AUTOSAR XML (schema 4-2-2)
package /STELLANTIS/EPT/ASWCs
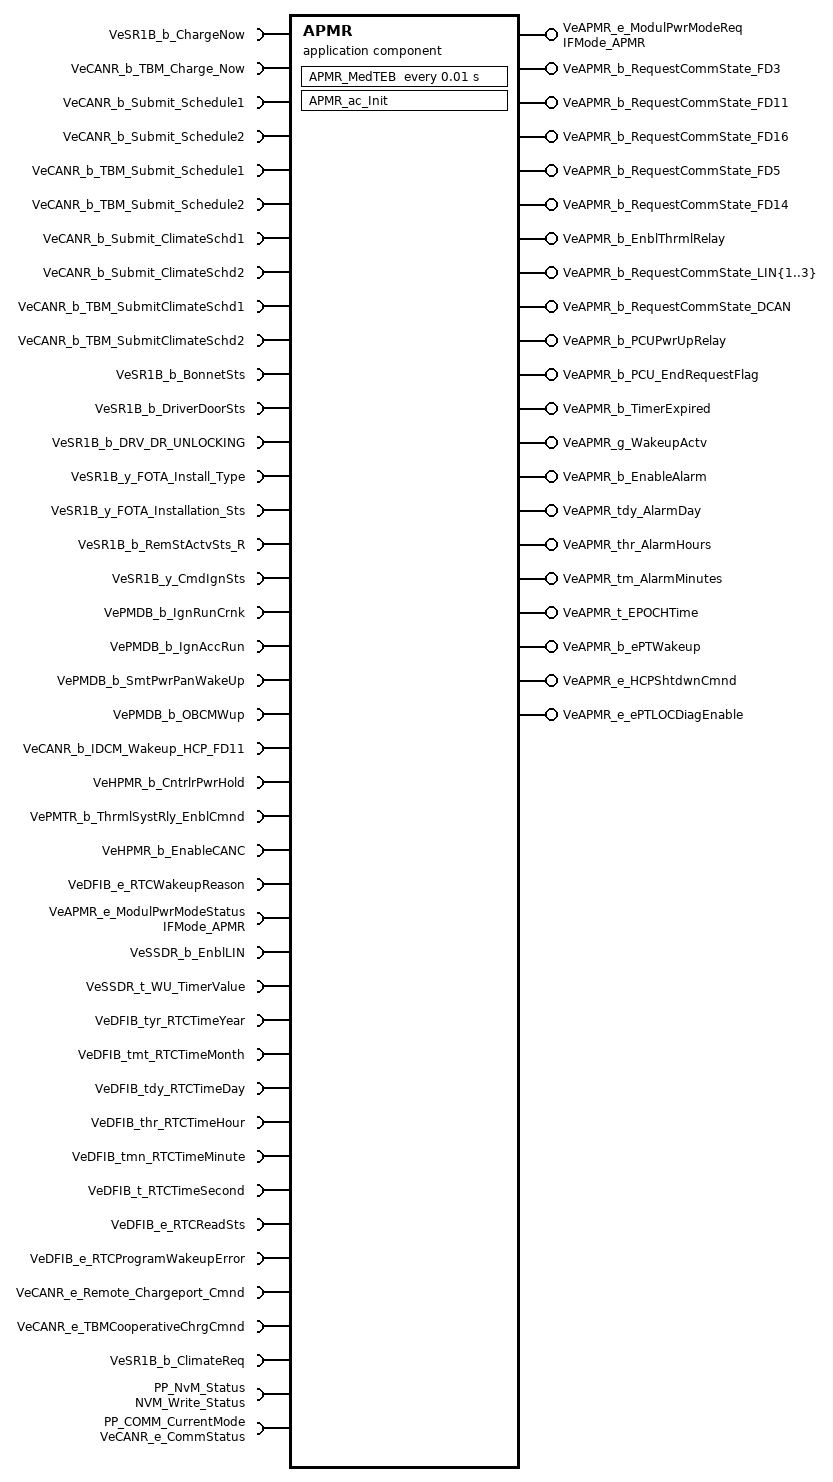
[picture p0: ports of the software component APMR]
  application sw component type APMR
    42 x require port:
      VeSR1B_b_ChargeNow: nonqueued-receiver-com-spec{data-element=Value, init-value=0}, required-interface=VeSR1B_b_ChargeNow
      VeCANR_b_TBM_Charge_Now: nonqueued-receiver-com-spec{data-element=VeCANR_b_TBM_Charge_Now, init-value=0}, required-interface=VeCANR_b_TBM_Charge_Now
      VeCANR_b_Submit_Schedule1: nonqueued-receiver-com-spec{data-element=VeCANR_b_Submit_Schedule1, init-value=0}, required-interface=VeCANR_b_Submit_Schedule1
      VeCANR_b_Submit_Schedule2: nonqueued-receiver-com-spec{data-element=VeCANR_b_Submit_Schedule2, init-value=0}, required-interface=VeCANR_b_Submit_Schedule2
      VeCANR_b_TBM_Submit_Schedule1: nonqueued-receiver-com-spec{data-element=VeCANR_b_TBM_Submit_Schedule1, init-value=0}, required-interface=VeCANR_b_TBM_Submit_Schedule1
      VeCANR_b_TBM_Submit_Schedule2: nonqueued-receiver-com-spec{data-element=VeCANR_b_TBM_Submit_Schedule2, init-value=0}, required-interface=VeCANR_b_TBM_Submit_Schedule2
      VeCANR_b_Submit_ClimateSchd1: nonqueued-receiver-com-spec{data-element=VeCANR_b_Submit_ClimateSchd1, init-value=0}, required-interface=VeCANR_b_Submit_ClimateSchd1
      VeCANR_b_Submit_ClimateSchd2: nonqueued-receiver-com-spec{data-element=VeCANR_b_Submit_ClimateSchd2, init-value=0}, required-interface=VeCANR_b_Submit_ClimateSchd2
      VeCANR_b_TBM_SubmitClimateSchd1: nonqueued-receiver-com-spec{data-element=VeCANR_b_TBM_SubmitClimateSchd1, init-value=0}, required-interface=VeCANR_b_TBM_SubmitClimateSchd1
      VeCANR_b_TBM_SubmitClimateSchd2: nonqueued-receiver-com-spec{data-element=VeCANR_b_TBM_SubmitClimateSchd2, init-value=0}, required-interface=VeCANR_b_TBM_SubmitClimateSchd2
      VeSR1B_b_BonnetSts: nonqueued-receiver-com-spec{data-element=Value, init-value=0}, required-interface=VeSR1B_b_BonnetSts
      VeSR1B_b_DriverDoorSts: nonqueued-receiver-com-spec{data-element=Value, init-value=0}, required-interface=VeSR1B_b_DriverDoorSts
      VeSR1B_b_DRV_DR_UNLOCKING: nonqueued-receiver-com-spec{data-element=Value, init-value=0}, required-interface=VeSR1B_b_DRV_DR_UNLOCKING
      VeSR1B_y_FOTA_Install_Type: nonqueued-receiver-com-spec{data-element=Value, init-value=0}, required-interface=VeSR1B_y_FOTA_Install_Type
      VeSR1B_y_FOTA_Installation_Sts: nonqueued-receiver-com-spec{data-element=Value, init-value=0}, required-interface=VeSR1B_y_FOTA_Installation_Sts
      VeSR1B_b_RemStActvSts_R: nonqueued-receiver-com-spec{data-element=Value, init-value=0}, required-interface=VeSR1B_b_RemStActvSts_R
      VeSR1B_y_CmdIgnSts: nonqueued-receiver-com-spec{data-element=Value, init-value=0}, required-interface=VeSR1B_y_CmdIgnSts
      VePMDB_b_IgnRunCrnk: nonqueued-receiver-com-spec{data-element=Value, init-value=0}, required-interface=VePMDB_b_IgnRunCrnk
      VePMDB_b_IgnAccRun: nonqueued-receiver-com-spec{data-element=Value, init-value=0}, required-interface=VePMDB_b_IgnAccRun
      VePMDB_b_SmtPwrPanWakeUp: nonqueued-receiver-com-spec{data-element=Value, init-value=0}, required-interface=VePMDB_b_SmtPwrPanWakeUp
      VePMDB_b_OBCMWup: nonqueued-receiver-com-spec{data-element=Value, init-value=0}, required-interface=VePMDB_b_OBCMWup
      VeCANR_b_IDCM_Wakeup_HCP_FD11: nonqueued-receiver-com-spec{data-element=VeCANR_b_IDCM_Wakeup_HCP_FD11, init-value=0}, required-interface=VeCANR_b_IDCM_Wakeup_HCP_FD11
      VeHPMR_b_CntrlrPwrHold: nonqueued-receiver-com-spec{data-element=Value, init-value=0}, required-interface=VeHPMR_b_CntrlrPwrHold
      VePMTR_b_ThrmlSystRly_EnblCmnd: nonqueued-receiver-com-spec{data-element=Value, init-value=0}, required-interface=VePMTR_b_ThrmlSystRly_EnblCmnd
      VeHPMR_b_EnableCANC: nonqueued-receiver-com-spec{data-element=Value, init-value=0}, required-interface=VeHPMR_b_EnableCANC
      VeDFIB_e_RTCWakeupReason: nonqueued-receiver-com-spec{data-element=Value, init-value=CeDFIB_e_RTC_NO_WAKEUP}, required-interface=VeDFIB_e_RTCWakeupReason
      VeAPMR_e_ModulPwrModeStatus: nonqueued-receiver-com-spec{data-element=Mode, init-value=0}, required-interface=IFMode_APMR
      VeSSDR_b_EnblLIN: nonqueued-receiver-com-spec{data-element=Value, init-value=0}, required-interface=VeSSDR_b_EnblLIN
      VeSSDR_t_WU_TimerValue: nonqueued-receiver-com-spec{data-element=Value, init-value=0}, required-interface=VeSSDR_t_WU_TimerValue
      VeDFIB_tyr_RTCTimeYear: nonqueued-receiver-com-spec{data-element=Value, init-value=0}, required-interface=VeDFIB_tyr_RTCTimeYear
      VeDFIB_tmt_RTCTimeMonth: nonqueued-receiver-com-spec{data-element=Value, init-value=0}, required-interface=VeDFIB_tmt_RTCTimeMonth
      VeDFIB_tdy_RTCTimeDay: nonqueued-receiver-com-spec{data-element=Value, init-value=0}, required-interface=VeDFIB_tdy_RTCTimeDay
      VeDFIB_thr_RTCTimeHour: nonqueued-receiver-com-spec{data-element=Value, init-value=0}, required-interface=VeDFIB_thr_RTCTimeHour
      VeDFIB_tmn_RTCTimeMinute: nonqueued-receiver-com-spec{data-element=Value, init-value=0}, required-interface=VeDFIB_tmn_RTCTimeMinute
      VeDFIB_t_RTCTimeSecond: nonqueued-receiver-com-spec{data-element=Value, init-value=0}, required-interface=VeDFIB_t_RTCTimeSecond
      VeDFIB_e_RTCReadSts: nonqueued-receiver-com-spec{data-element=Value, init-value=CeDFIB_e_RTCCallInit}, required-interface=VeDFIB_e_RTCReadSts
      VeDFIB_e_RTCProgramWakeupError: nonqueued-receiver-com-spec{data-element=Value, init-value=CeDFIB_e_RTCCallInit}, required-interface=VeDFIB_e_RTCProgramWakeupError
      VeCANR_e_Remote_Chargeport_Cmnd: nonqueued-receiver-com-spec{data-element=VeCANR_e_Remote_Chargeport_Cmnd, init-value=0}, required-interface=VeCANR_e_Remote_Chargeport_Cmnd
      VeCANR_e_TBMCooperativeChrgCmnd: nonqueued-receiver-com-spec{data-element=VeCANR_e_TBMCooperativeChrgCmnd, init-value=0}, required-interface=VeCANR_e_TBMCooperativeChrgCmnd
      VeSR1B_b_ClimateReq: nonqueued-receiver-com-spec{data-element=Value, init-value=0}, required-interface=VeSR1B_b_ClimateReq
      PP_NvM_Status: nonqueued-receiver-com-spec{data-element=NVM_Multiblock_WriteStatus, init-value=NVM_REQ_OK}, required-interface=NVM_Write_Status
      PP_COMM_CurrentMode: required-interface=VeCANR_e_CommStatus
        required-com-specs:
          data-element=VeCANR_e_CommStatus_DCAN, init-value=0
          data-element=VeCANR_e_CommStatus_FD11, init-value=0
          data-element=VeCANR_e_CommStatus_FD14, init-value=0
          data-element=VeCANR_e_CommStatus_FD16, init-value=0
          data-element=VeCANR_e_CommStatus_FD3, init-value=0
          data-element=VeCANR_e_CommStatus_FD5, init-value=0
          data-element=VeCANR_e_CommStatus_LIN{1..3}, init-value=0
    23 x provide port:
      VeAPMR_e_ModulPwrModeReq: nonqueued-sender-com-spec{data-element=Mode, init-value=0}, provided-interface=IFMode_APMR
      VeAPMR_b_RequestCommState_FD3: nonqueued-sender-com-spec{data-element=Value, init-value=0}, provided-interface=VeAPMR_b_RequestCommState_FD3
      VeAPMR_b_RequestCommState_FD11: nonqueued-sender-com-spec{data-element=Value, init-value=0}, provided-interface=VeAPMR_b_RequestCommState_FD11
      VeAPMR_b_RequestCommState_FD16: nonqueued-sender-com-spec{data-element=Value, init-value=0}, provided-interface=VeAPMR_b_RequestCommState_FD16
      VeAPMR_b_RequestCommState_FD5: nonqueued-sender-com-spec{data-element=Value, init-value=0}, provided-interface=VeAPMR_b_RequestCommState_FD5
      VeAPMR_b_RequestCommState_FD14: nonqueued-sender-com-spec{data-element=Value, init-value=0}, provided-interface=VeAPMR_b_RequestCommState_FD14
      VeAPMR_b_EnblThrmlRelay: nonqueued-sender-com-spec{data-element=Value, init-value=0}, provided-interface=VeAPMR_b_EnblThrmlRelay
      VeAPMR_b_RequestCommState_LIN{1..3}: nonqueued-sender-com-spec{data-element=Value, init-value=0}, provided-interface=VeAPMR_b_RequestCommState_LIN{1..3}
      VeAPMR_b_RequestCommState_DCAN: nonqueued-sender-com-spec{data-element=Value, init-value=0}, provided-interface=VeAPMR_b_RequestCommState_DCAN
      VeAPMR_b_PCUPwrUpRelay: nonqueued-sender-com-spec{data-element=Value, init-value=0}, provided-interface=VeAPMR_b_PCUPwrUpRelay
      VeAPMR_b_PCU_EndRequestFlag: nonqueued-sender-com-spec{data-element=Value, init-value=0}, provided-interface=VeAPMR_b_PCU_EndRequestFlag
      VeAPMR_b_TimerExpired: nonqueued-sender-com-spec{data-element=Value, init-value=0}, provided-interface=VeAPMR_b_TimerExpired
      VeAPMR_g_WakeupActv: nonqueued-sender-com-spec{data-element=Value, init-value=0}, provided-interface=VeAPMR_g_WakeupActv
      VeAPMR_b_EnableAlarm: nonqueued-sender-com-spec{data-element=Value, init-value=0}, provided-interface=VeAPMR_b_EnableAlarm
      VeAPMR_tdy_AlarmDay: nonqueued-sender-com-spec{data-element=Value, init-value=0}, provided-interface=VeAPMR_tdy_AlarmDay
      VeAPMR_thr_AlarmHours: nonqueued-sender-com-spec{data-element=Value, init-value=0}, provided-interface=VeAPMR_thr_AlarmHours
      VeAPMR_tm_AlarmMinutes: nonqueued-sender-com-spec{data-element=Value, init-value=0}, provided-interface=VeAPMR_tm_AlarmMinutes
      VeAPMR_t_EPOCHTime: nonqueued-sender-com-spec{data-element=Value, init-value=0}, provided-interface=VeAPMR_t_EPOCHTime
      VeAPMR_b_ePTWakeup: nonqueued-sender-com-spec{data-element=Value, init-value=0}, provided-interface=VeAPMR_b_ePTWakeup
      VeAPMR_e_HCPShtdwnCmnd: nonqueued-sender-com-spec{data-element=Value, init-value=CeAPMR_e_Default}, provided-interface=VeAPMR_e_HCPShtdwnCmnd
      VeAPMR_e_ePTLOCDiagEnable: nonqueued-sender-com-spec{data-element=Value, init-value=CeAPMR_e_ePTLOC_Default}, provided-interface=VeAPMR_e_ePTLOCDiagEnable
    behavior IB_APMR: data-type-mapping=[msADTtoIDTMapping, ADTtoIDTMapping], handle-termination-and-restart=NO-SUPPORT, included-data-type-set=data-type=[TeAPMR_e_CommStatus, TeAPMR_e_ModeReq, TeAPMR_e_NvMStatus, TeAPMR_e_SysState, TeCITR_e_CoopChargeCmd, TeCITR_e_FOTA_Install_Status, TeCITR_e_FOTA_Install_Type, TeCITR_e_RmtChargePortCmd, TePMDR_e_PowerMode]
      timing event Event_MedTEB: start-on-event=APMR_MedTEB, period=0.01
      init event Event_APMR_ac_Init: start-on-event=APMR_ac_Init
      runnable APMR_ac_Init
        data-send-points:
          4 x access:
            OUT_VeAPMR_e_ModulPwrModeReq_Mode: accessed-variable=VeAPMR_e_ModulPwrModeReq.Mode
            OUT_VeAPMR_b_PCU_EndRequestFlag_Value: accessed-variable=VeAPMR_b_PCU_EndRequestFlag.Value
            OUT_VeAPMR_e_HCPShtdwnCmnd_Value: accessed-variable=VeAPMR_e_HCPShtdwnCmnd.Value
            OUT_VeAPMR_e_ePTLOCDiagEnable_Value: accessed-variable=VeAPMR_e_ePTLOCDiagEnable.Value
      runnable APMR_MedTEB
        data-receive-point-by-arguments:
          50 x access:
            IN_PP_COMM_CurrentMode_VeCANR_e_CommStatus_DCAN: accessed-variable=PP_COMM_CurrentMode.VeCANR_e_CommStatus_DCAN
            IN_PP_COMM_CurrentMode_VeCANR_e_CommStatus_FD11: accessed-variable=PP_COMM_CurrentMode.VeCANR_e_CommStatus_FD11
            IN_PP_COMM_CurrentMode_VeCANR_e_CommStatus_FD14: accessed-variable=PP_COMM_CurrentMode.VeCANR_e_CommStatus_FD14
            IN_PP_COMM_CurrentMode_VeCANR_e_CommStatus_FD16: accessed-variable=PP_COMM_CurrentMode.VeCANR_e_CommStatus_FD16
            IN_PP_COMM_CurrentMode_VeCANR_e_CommStatus_FD3: accessed-variable=PP_COMM_CurrentMode.VeCANR_e_CommStatus_FD3
            IN_PP_COMM_CurrentMode_VeCANR_e_CommStatus_FD5: accessed-variable=PP_COMM_CurrentMode.VeCANR_e_CommStatus_FD5
            IN_PP_COMM_CurrentMode_VeCANR_e_CommStatus_LIN{1..3}: accessed-variable=PP_COMM_CurrentMode.VeCANR_e_CommStatus_LIN{1..3}
            IN_PP_NvM_Status_NVM_Multiblock_WriteStatus: accessed-variable=PP_NvM_Status.NVM_Multiblock_WriteStatus
            IN_VeAPMR_e_ModulPwrModeStatus_Mode: accessed-variable=VeAPMR_e_ModulPwrModeStatus.Mode
            IN_VeCANR_b_IDCM_Wakeup_HCP_FD11_VeCANR_b_IDCM_Wakeup_HCP_FD11: accessed-variable=VeCANR_b_IDCM_Wakeup_HCP_FD11.VeCANR_b_IDCM_Wakeup_HCP_FD11
            IN_VeCANR_b_Submit_ClimateSchd1_VeCANR_b_Submit_ClimateSchd1: accessed-variable=VeCANR_b_Submit_ClimateSchd1.VeCANR_b_Submit_ClimateSchd1
            IN_VeCANR_b_Submit_ClimateSchd2_VeCANR_b_Submit_ClimateSchd2: accessed-variable=VeCANR_b_Submit_ClimateSchd2.VeCANR_b_Submit_ClimateSchd2
            IN_VeCANR_b_Submit_Schedule1_VeCANR_b_Submit_Schedule1: accessed-variable=VeCANR_b_Submit_Schedule1.VeCANR_b_Submit_Schedule1
            IN_VeCANR_b_Submit_Schedule2_VeCANR_b_Submit_Schedule2: accessed-variable=VeCANR_b_Submit_Schedule2.VeCANR_b_Submit_Schedule2
            IN_VeCANR_b_TBM_Charge_Now_VeCANR_b_TBM_Charge_Now: accessed-variable=VeCANR_b_TBM_Charge_Now.VeCANR_b_TBM_Charge_Now
            IN_VeCANR_b_TBM_SubmitClimateSchd1_VeCANR_b_TBM_SubmitClimateSchd1: accessed-variable=VeCANR_b_TBM_SubmitClimateSchd1.VeCANR_b_TBM_SubmitClimateSchd1
            IN_VeCANR_b_TBM_SubmitClimateSchd2_VeCANR_b_TBM_SubmitClimateSchd2: accessed-variable=VeCANR_b_TBM_SubmitClimateSchd2.VeCANR_b_TBM_SubmitClimateSchd2
            IN_VeCANR_b_TBM_Submit_Schedule1_VeCANR_b_TBM_Submit_Schedule1: accessed-variable=VeCANR_b_TBM_Submit_Schedule1.VeCANR_b_TBM_Submit_Schedule1
            IN_VeCANR_b_TBM_Submit_Schedule2_VeCANR_b_TBM_Submit_Schedule2: accessed-variable=VeCANR_b_TBM_Submit_Schedule2.VeCANR_b_TBM_Submit_Schedule2
            IN_VeCANR_e_Remote_Chargeport_Cmnd_VeCANR_e_Remote_Chargeport_Cmnd: accessed-variable=VeCANR_e_Remote_Chargeport_Cmnd.VeCANR_e_Remote_Chargeport_Cmnd
            IN_VeCANR_e_TBMCooperativeChrgCmnd_VeCANR_e_TBMCooperativeChrgCmnd: accessed-variable=VeCANR_e_TBMCooperativeChrgCmnd.VeCANR_e_TBMCooperativeChrgCmnd
            IN_VeDFIB_e_RTCProgramWakeupError_Value: accessed-variable=VeDFIB_e_RTCProgramWakeupError.Value
            IN_VeDFIB_e_RTCReadSts_Value: accessed-variable=VeDFIB_e_RTCReadSts.Value
            IN_VeDFIB_e_RTCWakeupReason_Value: accessed-variable=VeDFIB_e_RTCWakeupReason.Value
            IN_VeDFIB_t_RTCTimeSecond_Value: accessed-variable=VeDFIB_t_RTCTimeSecond.Value
            IN_VeDFIB_tdy_RTCTimeDay_Value: accessed-variable=VeDFIB_tdy_RTCTimeDay.Value
            IN_VeDFIB_thr_RTCTimeHour_Value: accessed-variable=VeDFIB_thr_RTCTimeHour.Value
            IN_VeDFIB_tmn_RTCTimeMinute_Value: accessed-variable=VeDFIB_tmn_RTCTimeMinute.Value
            IN_VeDFIB_tmt_RTCTimeMonth_Value: accessed-variable=VeDFIB_tmt_RTCTimeMonth.Value
            IN_VeDFIB_tyr_RTCTimeYear_Value: accessed-variable=VeDFIB_tyr_RTCTimeYear.Value
            IN_VeHPMR_b_CntrlrPwrHold_Value: accessed-variable=VeHPMR_b_CntrlrPwrHold.Value
            IN_VeHPMR_b_EnableCANC_Value: accessed-variable=VeHPMR_b_EnableCANC.Value
            IN_VePMDB_b_IgnAccRun_Value: accessed-variable=VePMDB_b_IgnAccRun.Value
            IN_VePMDB_b_IgnRunCrnk_Value: accessed-variable=VePMDB_b_IgnRunCrnk.Value
            IN_VePMDB_b_OBCMWup_Value: accessed-variable=VePMDB_b_OBCMWup.Value
            IN_VePMDB_b_SmtPwrPanWakeUp_Value: accessed-variable=VePMDB_b_SmtPwrPanWakeUp.Value
            IN_VePMTR_b_ThrmlSystRly_EnblCmnd_Value: accessed-variable=VePMTR_b_ThrmlSystRly_EnblCmnd.Value
            IN_VeSR1B_b_BonnetSts_Value: accessed-variable=VeSR1B_b_BonnetSts.Value
            IN_VeSR1B_b_ChargeNow_Value: accessed-variable=VeSR1B_b_ChargeNow.Value
            IN_VeSR1B_b_ClimateReq_Value: accessed-variable=VeSR1B_b_ClimateReq.Value
            IN_VeSR1B_b_DRV_DR_UNLOCKING_Value: accessed-variable=VeSR1B_b_DRV_DR_UNLOCKING.Value
            IN_VeSR1B_b_DriverDoorSts_Value: accessed-variable=VeSR1B_b_DriverDoorSts.Value
            IN_VeSR1B_b_RemStActvSts_R_Value: accessed-variable=VeSR1B_b_RemStActvSts_R.Value
            IN_VeSR1B_y_CmdIgnSts_Value: accessed-variable=VeSR1B_y_CmdIgnSts.Value
            IN_VeSR1B_y_FOTA_Install_Type_Value: accessed-variable=VeSR1B_y_FOTA_Install_Type.Value
            IN_VeSR1B_y_FOTA_Installation_Sts_Value: accessed-variable=VeSR1B_y_FOTA_Installation_Sts.Value
            IN_VeSSDR_b_EnblLIN_Value: accessed-variable=VeSSDR_b_EnblLIN.Value
            IN_VeSSDR_t_WU_TimerValue_Value: accessed-variable=VeSSDR_t_WU_TimerValue.Value
        data-send-points:
          23 x access:
            OUT_VeAPMR_e_ModulPwrModeReq_Mode: accessed-variable=VeAPMR_e_ModulPwrModeReq.Mode
            OUT_VeAPMR_b_RequestCommState_FD3_Value: accessed-variable=VeAPMR_b_RequestCommState_FD3.Value
            OUT_VeAPMR_b_RequestCommState_FD11_Value: accessed-variable=VeAPMR_b_RequestCommState_FD11.Value
            OUT_VeAPMR_b_RequestCommState_FD16_Value: accessed-variable=VeAPMR_b_RequestCommState_FD16.Value
            OUT_VeAPMR_b_RequestCommState_FD5_Value: accessed-variable=VeAPMR_b_RequestCommState_FD5.Value
            OUT_VeAPMR_b_RequestCommState_FD14_Value: accessed-variable=VeAPMR_b_RequestCommState_FD14.Value
            OUT_VeAPMR_b_EnblThrmlRelay_Value: accessed-variable=VeAPMR_b_EnblThrmlRelay.Value
            OUT_VeAPMR_b_RequestCommState_LIN{1..3}_Value: accessed-variable=VeAPMR_b_RequestCommState_LIN{1..3}.Value
            OUT_VeAPMR_b_RequestCommState_DCAN_Value: accessed-variable=VeAPMR_b_RequestCommState_DCAN.Value
            OUT_VeAPMR_b_PCUPwrUpRelay_Value: accessed-variable=VeAPMR_b_PCUPwrUpRelay.Value
            OUT_VeAPMR_b_PCU_EndRequestFlag_Value: accessed-variable=VeAPMR_b_PCU_EndRequestFlag.Value
            OUT_VeAPMR_b_TimerExpired_Value: accessed-variable=VeAPMR_b_TimerExpired.Value
            OUT_VeAPMR_g_WakeupActv_Value: accessed-variable=VeAPMR_g_WakeupActv.Value
            OUT_VeAPMR_b_EnableAlarm_Value: accessed-variable=VeAPMR_b_EnableAlarm.Value
            OUT_VeAPMR_tdy_AlarmDay_Value: accessed-variable=VeAPMR_tdy_AlarmDay.Value
            OUT_VeAPMR_thr_AlarmHours_Value: accessed-variable=VeAPMR_thr_AlarmHours.Value
            OUT_VeAPMR_tm_AlarmMinutes_Value: accessed-variable=VeAPMR_tm_AlarmMinutes.Value
            OUT_VeAPMR_t_EPOCHTime_Value: accessed-variable=VeAPMR_t_EPOCHTime.Value
            OUT_VeAPMR_b_ePTWakeup_Value: accessed-variable=VeAPMR_b_ePTWakeup.Value
            OUT_VeAPMR_e_HCPShtdwnCmnd_Value: accessed-variable=VeAPMR_e_HCPShtdwnCmnd.Value
            OUT_VeAPMR_e_ePTLOCDiagEnable_Value: accessed-variable=VeAPMR_e_ePTLOCDiagEnable.Value
